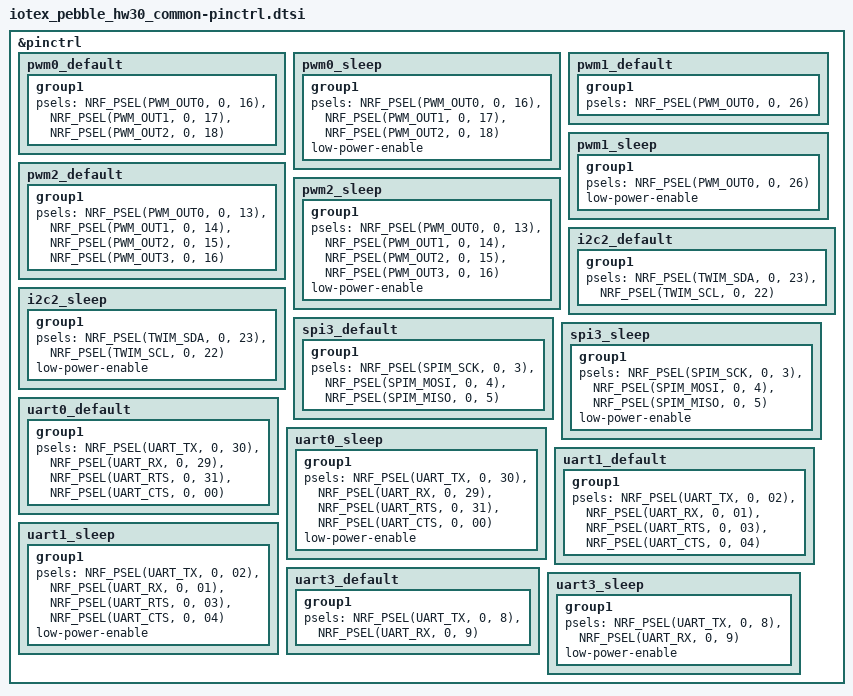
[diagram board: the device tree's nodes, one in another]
&pinctrl {
	pwm0_default: pwm0_default {
		group1 {
			psels = <NRF_PSEL(PWM_OUT0, 0, 16)>,
				<NRF_PSEL(PWM_OUT1, 0, 17)>,
				<NRF_PSEL(PWM_OUT2, 0, 18)>;
		};
	};

	pwm0_sleep: pwm0_sleep {
		group1 {
			psels = <NRF_PSEL(PWM_OUT0, 0, 16)>,
				<NRF_PSEL(PWM_OUT1, 0, 17)>,
				<NRF_PSEL(PWM_OUT2, 0, 18)>;
			low-power-enable;
		};
	};

	pwm1_default: pwm1_default {
		group1 {
			psels = <NRF_PSEL(PWM_OUT0, 0, 26)>;
		};
	};

	pwm1_sleep: pwm1_sleep {
		group1 {
			psels = <NRF_PSEL(PWM_OUT0, 0, 26)>;
			low-power-enable;
		};
	};

	pwm2_default: pwm2_default {
		group1 {
			psels = <NRF_PSEL(PWM_OUT0, 0, 13)>,
				<NRF_PSEL(PWM_OUT1, 0, 14)>,
				<NRF_PSEL(PWM_OUT2, 0, 15)>,
				<NRF_PSEL(PWM_OUT3, 0, 16)>;
		};
	};

	pwm2_sleep: pwm2_sleep {
		group1 {
			psels = <NRF_PSEL(PWM_OUT0, 0, 13)>,
				<NRF_PSEL(PWM_OUT1, 0, 14)>,
				<NRF_PSEL(PWM_OUT2, 0, 15)>,
				<NRF_PSEL(PWM_OUT3, 0, 16)>;
			low-power-enable;
		};
	};

	i2c2_default: i2c2_default {
		group1 {
			psels = <NRF_PSEL(TWIM_SDA, 0, 23)>,
				<NRF_PSEL(TWIM_SCL, 0, 22)>;
		};
	};

	i2c2_sleep: i2c2_sleep {
		group1 {
			psels = <NRF_PSEL(TWIM_SDA, 0, 23)>,
				<NRF_PSEL(TWIM_SCL, 0, 22)>;
			low-power-enable;
		};
	};

	spi3_default: spi3_default {
		group1 {
			psels = <NRF_PSEL(SPIM_SCK, 0, 3)>,
				<NRF_PSEL(SPIM_MOSI, 0, 4)>,
				<NRF_PSEL(SPIM_MISO, 0, 5)>;
		};
	};

	spi3_sleep: spi3_sleep {
		group1 {
			psels = <NRF_PSEL(SPIM_SCK, 0, 3)>,
				<NRF_PSEL(SPIM_MOSI, 0, 4)>,
				<NRF_PSEL(SPIM_MISO, 0, 5)>;
			low-power-enable;
		};
	};

	uart0_default: uart0_default {
		group1 {
			psels = <NRF_PSEL(UART_TX, 0, 30)>,
				<NRF_PSEL(UART_RX, 0, 29)>,
				<NRF_PSEL(UART_RTS, 0, 31)>,
				<NRF_PSEL(UART_CTS, 0, 00)>;
		};
	};

	uart0_sleep: uart0_sleep {
		group1 {
			psels = <NRF_PSEL(UART_TX, 0, 30)>,
				<NRF_PSEL(UART_RX, 0, 29)>,
				<NRF_PSEL(UART_RTS, 0, 31)>,
				<NRF_PSEL(UART_CTS, 0, 00)>;
			low-power-enable;
		};
	};

	uart1_default: uart1_default {
		group1 {
			psels = <NRF_PSEL(UART_TX, 0, 02)>,
				<NRF_PSEL(UART_RX, 0, 01)>,
				<NRF_PSEL(UART_RTS, 0, 03)>,
				<NRF_PSEL(UART_CTS, 0, 04)>;
		};
	};

	uart1_sleep: uart1_sleep {
		group1 {
			psels = <NRF_PSEL(UART_TX, 0, 02)>,
				<NRF_PSEL(UART_RX, 0, 01)>,
				<NRF_PSEL(UART_RTS, 0, 03)>,
				<NRF_PSEL(UART_CTS, 0, 04)>;
			low-power-enable;
		};
	};

	uart3_default: uart3_default {
		group1 {
			psels = <NRF_PSEL(UART_TX, 0, 8)>,
				<NRF_PSEL(UART_RX, 0, 9)>;
		};
	};

	uart3_sleep: uart3_sleep {
		group1 {
			psels = <NRF_PSEL(UART_TX, 0, 8)>,
				<NRF_PSEL(UART_RX, 0, 9)>;
			low-power-enable;
		};
	};

};
